# WDOGSAFE2 register map
Registers from a debugger description file.
Registers are 32-bit, write-only, no defined reset value unless marked. A register's access mark holds for its fields unless they carry their own. Addresses are absolute; registers are grouped by the start of their names; lines under a group give offsets from that group; [hi:lo] are bit positions; {n}, {i} and the like mark numbered series; 'fields as' and 'values as' point back to an identical list; <NAME> marks a mode.

## WDOGSAFE2
0x51004000 WDOGSAFE2/LoadMaxCount access not given
  [15:0] LoadMaxCount
0x51004004 WDOGSAFE2/CurrentMaxCount ro
  [15:0] CurrentMaxCount
0x51004008 WDOGSAFE2/LoadMinCount access not given
  [15:0] LoadMinCount
0x5100400C WDOGSAFE2/CurrentMinCount ro
  [15:0] CurrentMinCount
0x51004010 WDOGSAFE2/StatusInt0 ro
  [0] StatusInt0
0x51004014 WDOGSAFE2/StatusInt1 ro
  [0] StatusInt1
0x51004018 WDOGSAFE2/ClearInt ro
  [0] ClearInt
0x5100401C WDOGSAFE2/Control access not given
  [0] MaskInt
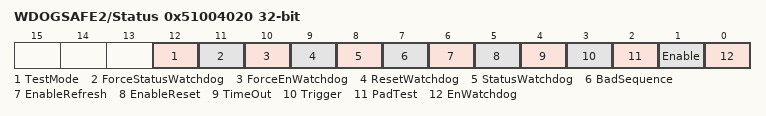
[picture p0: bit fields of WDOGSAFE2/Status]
0x51004020 WDOGSAFE2/Status ro
  [12] TestMode, [11] ForceStatusWatchdog, [10] ForceEnWatchdog, [9] ResetWatchdog, [8] StatusWatchdog, [7] BadSequence, [6] EnableRefresh, [5] EnableReset, [4] TimeOut, [3] Trigger, [2] PadTest, [1] Enable, [0] EnWatchdog
0x51004024 WDOGSAFE2/Refresh
  [31:0] Refresh
0x51004028 WDOGSAFE2/SetEnableRefresh
  [31:0] SetEnableRefresh
0x5100402C WDOGSAFE2/ClearEnableRefresh
  [31:0] ClearEnableRefresh
0x51004030 WDOGSAFE2/SetEnableReset
  [31:0] SetEnableReset
0x51004034 WDOGSAFE2/ClearEnableReset
  [31:0] ClearEnableReset
0x51004038 WDOGSAFE2/SetTrigger
  [31:0] SetTrigger
0x5100403C WDOGSAFE2/SetPadTest
  [31:0] SetPadTest
0x51004040 WDOGSAFE2/ClearPadTest
  [31:0] ClearPadTest
0x51004044 WDOGSAFE2/SetEnable
  [31:0] SetEnable
0x51004048 WDOGSAFE2/ClearEnable
  [31:0] ClearEnable
0x5100404C WDOGSAFE2/SetTestMode
  [31:0] SetTestMode
0x51004050 WDOGSAFE2/ClearTestMode
  [31:0] ClearTestMode
0x51004054 WDOGSAFE2/SetForceEnWatchdog
  [31:0] SetForceEnWatchdog
0x51004058 WDOGSAFE2/ClearForceEnWatchdog
  [31:0] ClearForceEnWatchdog
0x5100405C WDOGSAFE2/SetForceStatusWatchdog
  [31:0] SetForceStatusWatchdog
0x51004060 WDOGSAFE2/ClearForceStatusWatchdog
  [31:0] ClearForceStatusWatchdog
